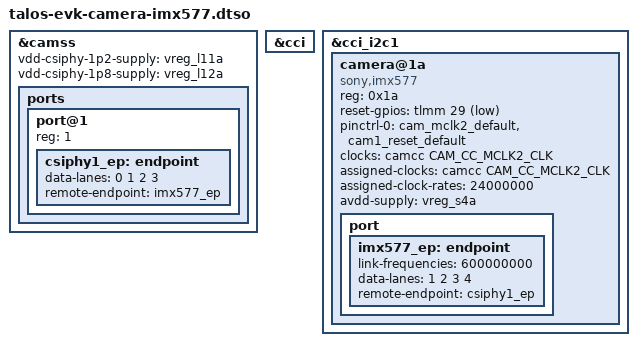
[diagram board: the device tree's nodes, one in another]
// SPDX-License-Identifier: BSD-3-Clause
/*
 * Copyright (c) Qualcomm Technologies, Inc. and/or its subsidiaries.
 */

/dts-v1/;
/plugin/;

#include <dt-bindings/clock/qcom,qcs615-camcc.h>
#include <dt-bindings/gpio/gpio.h>

&camss {
	vdd-csiphy-1p2-supply = <&vreg_l11a>;
	vdd-csiphy-1p8-supply = <&vreg_l12a>;

	status = "okay";

	ports {
		#address-cells = <1>;
		#size-cells = <0>;

		port@1 {
			reg = <1>;

			csiphy1_ep: endpoint {
				data-lanes = <0 1 2 3>;
				remote-endpoint = <&imx577_ep>;
			};
		};
	};
};

&cci {
	status = "okay";
};

&cci_i2c1 {
	#address-cells = <1>;
	#size-cells = <0>;

	camera@1a {
		compatible = "sony,imx577";
		reg = <0x1a>;

		reset-gpios = <&tlmm 29 GPIO_ACTIVE_LOW>;
		pinctrl-0 = <&cam_mclk2_default &cam1_reset_default>;
		pinctrl-names = "default";

		clocks = <&camcc CAM_CC_MCLK2_CLK>;
		assigned-clocks = <&camcc CAM_CC_MCLK2_CLK>;
		assigned-clock-rates = <24000000>;

		avdd-supply = <&vreg_s4a>;

		port {
			imx577_ep: endpoint {
				link-frequencies = /bits/ 64 <600000000>;
				data-lanes = <1 2 3 4>;
				remote-endpoint = <&csiphy1_ep>;
			};
		};
	};
};
